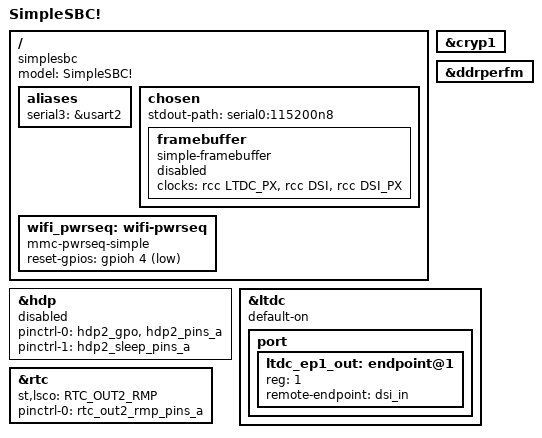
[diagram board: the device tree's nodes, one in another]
// SPDX-License-Identifier: (GPL-2.0-only OR BSD-3-Clause)
/*
 * Copyright (C) STMicroelectronics 2023 - All Rights Reserved
 * Author: Alexandre Torgue <alexandre.torgue@foss.st.com> for STMicroelectronics.
 */

/dts-v1/;

#include "stm32mp157.dtsi"
#include "stm32mp15xf.dtsi"
#include "stm32mp15-pinctrl.dtsi"
#include "stm32mp15xxac-pinctrl.dtsi"
#include "stm32mp15xx-dkx.dtsi"
#include "stm32mp157c-dk2-scmi.dtsi"
#include <dt-bindings/rtc/rtc-stm32.h>

/ {
	model = "SimpleSBC!";
	compatible = "simplesbc", "st,stm32mp157";

	aliases {
		serial3 = &usart2;
	};

	chosen {
		#address-cells = <1>;
		#size-cells = <1>;
		ranges;
		stdout-path = "serial0:115200n8";

		framebuffer {
			compatible = "simple-framebuffer";
			clocks = <&rcc LTDC_PX>, <&rcc DSI>, <&rcc DSI_PX>;
			status = "disabled";
		};
	};

	wifi_pwrseq: wifi-pwrseq {
		compatible = "mmc-pwrseq-simple";
		reset-gpios = <&gpioh 4 GPIO_ACTIVE_LOW>;
	};
};

&cryp1 {
	status = "okay";
};

&ddrperfm {
	status = "okay";
};

&hdp {
	pinctrl-names = "default", "sleep";
	pinctrl-0 = <&hdp2_gpo &hdp2_pins_a>;
	pinctrl-1 = <&hdp2_sleep_pins_a>;
	status = "disabled";
};

&ltdc {
	default-on;
	status = "okay";

	port {
		#address-cells = <1>;
		#size-cells = <0>;

		ltdc_ep1_out: endpoint@1 {
			reg = <1>;
			remote-endpoint = <&dsi_in>;
		};
	};
};

&rtc {
	st,lsco = <RTC_OUT2_RMP>;
	pinctrl-0 = <&rtc_out2_rmp_pins_a>;
	pinctrl-names = "default";
};
